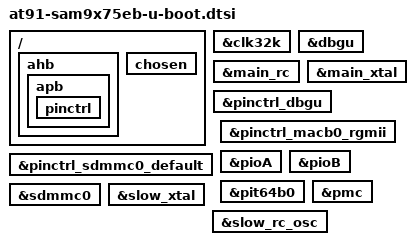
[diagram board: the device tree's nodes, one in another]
// SPDX-License-Identifier: (GPL-2.0+ OR MIT)
/*
 * at91-sam9x75eb-u-boot.dts - Device Tree file for SAM9X75-EB board.
 *
 * Copyright (C) 2022 Microchip Technology Inc. and its subsidiaries
 */

/ {
	ahb {
		bootph-all;

		apb {
			bootph-all;

			pinctrl {
				bootph-all;
			};
		};
	};

	chosen {
		bootph-all;
	};
};

&clk32k {
	bootph-all;
};

&dbgu {
	bootph-all;
};

&main_rc {
	bootph-all;
};

&main_xtal {
	bootph-all;
};

&pinctrl_dbgu {
	bootph-all;
};

&pinctrl_sdmmc0_default {
	bootph-all;
};

&pinctrl_macb0_rgmii {
	bootph-all;
};

&pioA {
	bootph-all;
};

&pioB {
	bootph-all;
};

&pit64b0 {
	bootph-all;
};

&pmc {
	bootph-all;
};

&sdmmc0 {
	bootph-all;
};

&slow_xtal {
	bootph-all;
};

&slow_rc_osc {
	bootph-all;
};
